AUTOSAR XML (schema 00044)
package /E40_Platform_System_SystemPackage/Components
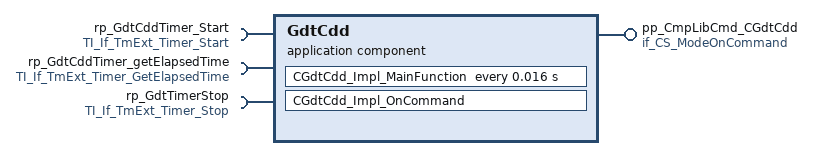
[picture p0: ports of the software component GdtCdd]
  application sw component type GdtCdd
    provide port pp_CmpLibCmd_CGdtCdd: server-com-spec{operation=Impl_OnCommand, queue-length=1}, provided-interface=if_CS_ModeOnCommand
    require port rp_GdtCddTimer_Start: client-com-spec=Timer_Start, required-interface=TI_If_TmExt_Timer_Start
    require port rp_GdtCddTimer_getElapsedTime: client-com-spec=Timer_GetElapsedTime, required-interface=TI_If_TmExt_Timer_GetElapsedTime
    require port rp_GdtTimerStop: client-com-spec=Timer_Stop, required-interface=TI_If_TmExt_Timer_Stop
    behavior IB_GdtCdd
      timing event TECGdtCdd_Impl_MainFunction: start-on-event=CGdtCdd_Impl_MainFunction, period=0.016
      operation invoked event OIE_pp_CmpLibCmd_CGdtCdd_CGdtCdd_Impl_OnCommandTrigByImpl_OnCommand: start-on-event=CGdtCdd_Impl_OnCommand, operation=pp_CmpLibCmd_CGdtCdd.Impl_OnCommand
      port-api-options:
        enable-take-address=false, indirect-api=false, port=pp_CmpLibCmd_CGdtCdd
        enable-take-address=false, indirect-api=false, port=rp_GdtCddTimer_Start
        enable-take-address=false, indirect-api=false, port=rp_GdtCddTimer_getElapsedTime
        enable-take-address=false, indirect-api=false, port=rp_GdtTimerStop
      runnable CGdtCdd_Impl_MainFunction: can-be-invoked-concurrently=true
        sync call OA_rp_GdtCddTimer_Start_Timer_Start: operation=rp_GdtCddTimer_Start.Timer_Start
        sync call OA_rp_GdtCddTimer_getElapsedTime_Timer_GetElapsedTime: operation=rp_GdtCddTimer_getElapsedTime.Timer_GetElapsedTime
        sync call OA_rp_GdtTimerStop_Timer_Stop: operation=rp_GdtTimerStop.Timer_Stop
      runnable CGdtCdd_Impl_OnCommand: can-be-invoked-concurrently=true
  swc implementation IMPL_GdtCdd: behavior=IB_GdtCdd
